AUTOSAR XML (schema 00053)
package /Swcs
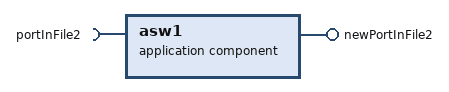
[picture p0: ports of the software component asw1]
  application sw component type asw1
    require port portInFile2
    provide port newPortInFile2
